VERSION "HIPBYYYYYYYYYYYYYYYYYYYYYYYYYYYYNNNNNNNNNN/4/%%%/4/'%**4NNN///"

NS_ :

BS_:

BU_: ADMM_05431 ADMM_05432 CSM_GmbH

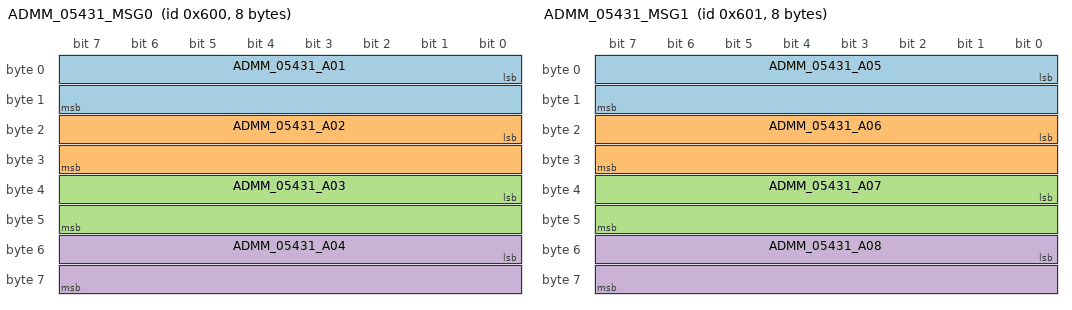
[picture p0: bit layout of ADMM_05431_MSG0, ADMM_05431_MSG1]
BO_ 1536 ADMM_05431_MSG0: 8 ADMM_05431
 SG_ ADMM_05431_A01 : 0|16@1- (0.00061037019,0) [-20|20] "V" CSM_GmbH
 SG_ ADMM_05431_A02 : 16|16@1- (0.00061037019,0) [-20|20] "V" CSM_GmbH
 SG_ ADMM_05431_A03 : 32|16@1- (0.00061037019,0) [-20|20] "V" CSM_GmbH
 SG_ ADMM_05431_A04 : 48|16@1- (0.00061037019,0) [-20|20] "V" CSM_GmbH

BO_ 1537 ADMM_05431_MSG1: 8 ADMM_05431
 SG_ ADMM_05431_A05 : 0|16@1- (0.00061037019,0) [-20|20] "V" CSM_GmbH
 SG_ ADMM_05431_A06 : 16|16@1- (0.00061037019,0) [-20|20] "V" CSM_GmbH
 SG_ ADMM_05431_A07 : 32|16@1- (0.00061037019,0) [-20|20] "V" CSM_GmbH
 SG_ ADMM_05431_A08 : 48|16@1- (0.00061037019,0) [-20|20] "V" CSM_GmbH

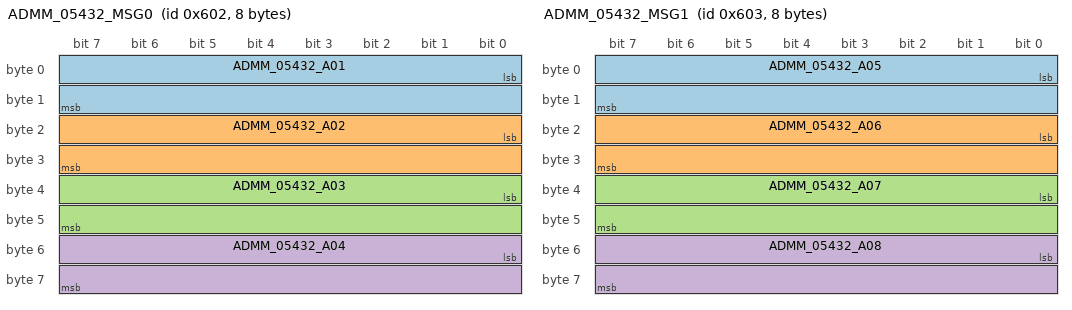
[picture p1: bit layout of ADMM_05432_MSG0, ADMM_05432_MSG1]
BO_ 1538 ADMM_05432_MSG0: 8 ADMM_05432
 SG_ ADMM_05432_A01 : 0|16@1- (0.00061037019,0) [-20|20] "V" CSM_GmbH
 SG_ ADMM_05432_A02 : 16|16@1- (0.00061037019,0) [-20|20] "V" CSM_GmbH
 SG_ ADMM_05432_A03 : 32|16@1- (0.00061037019,0) [-20|20] "V" CSM_GmbH
 SG_ ADMM_05432_A04 : 48|16@1- (0.00061037019,0) [-20|20] "V" CSM_GmbH

BO_ 1539 ADMM_05432_MSG1: 8 ADMM_05432
 SG_ ADMM_05432_A05 : 0|16@1- (0.00061037019,0) [-20|20] "V" CSM_GmbH
 SG_ ADMM_05432_A06 : 16|16@1- (0.00061037019,0) [-20|20] "V" CSM_GmbH
 SG_ ADMM_05432_A07 : 32|16@1- (0.00061037019,0) [-20|20] "V" CSM_GmbH
 SG_ ADMM_05432_A08 : 48|16@1- (0.00061037019,0) [-20|20] "V" CSM_GmbH

CM_ "CSM = 3, 11, 500000, 66, [305969] DBV(0) CONFIG(7.8.1.4033) IDINCR(1)";
CM_ BU_ ADMM_05431 "CSM = 3, MiniModulAD, 0, 8, 0x600, 0, 5431, 2, -ADMD, 1089, 0, 0, 0, 0, 15, 0x44303030, 4, 0x1";
CM_ SG_ 1536 ADMM_05431_A01 "CSM = 0, 0, 0, 0, 20, 1, 0, 0, 0, 0 ST(3) ZCMP(0,0)";
CM_ SG_ 1536 ADMM_05431_A02 "CSM = 0, 0, 0, 0, 20, 1, 0, 0, 0, 0 ST(3) ZCMP(0,0)";
CM_ SG_ 1536 ADMM_05431_A03 "CSM = 0, 0, 0, 0, 20, 1, 0, 0, 0, 0 ST(3) ZCMP(0,0)";
CM_ SG_ 1536 ADMM_05431_A04 "CSM = 0, 0, 0, 0, 20, 1, 0, 0, 0, 0 ST(3) ZCMP(0,0)";
CM_ SG_ 1537 ADMM_05431_A05 "CSM = 0, 0, 0, 0, 20, 1, 0, 0, 0, 0 ST(3) ZCMP(0,0)";
CM_ SG_ 1537 ADMM_05431_A06 "CSM = 0, 0, 0, 0, 20, 1, 0, 0, 0, 0 ST(3) ZCMP(0,0)";
CM_ SG_ 1537 ADMM_05431_A07 "CSM = 0, 0, 0, 0, 20, 1, 0, 0, 0, 0 ST(3) ZCMP(0,0)";
CM_ SG_ 1537 ADMM_05431_A08 "CSM = 0, 0, 0, 0, 20, 1, 0, 0, 0, 0 ST(3) ZCMP(0,0)";
CM_ BU_ ADMM_05432 "CSM = 3, MiniModulAD, 0, 8, 0x602, 0, 5432, 2, -ADMD, 1089, 0, 0, 0, 0, 15, 0x44303030, 4, 0x1";
CM_ SG_ 1538 ADMM_05432_A01 "CSM = 0, 0, 0, 0, 20, 1, 0, 0, 0, 0 ST(3) ZCMP(0,0)";
CM_ SG_ 1538 ADMM_05432_A02 "CSM = 0, 0, 0, 0, 20, 1, 0, 0, 0, 0 ST(3) ZCMP(0,0)";
CM_ SG_ 1538 ADMM_05432_A03 "CSM = 0, 0, 0, 0, 20, 1, 0, 0, 0, 0 ST(3) ZCMP(0,0)";
CM_ SG_ 1538 ADMM_05432_A04 "CSM = 0, 0, 0, 0, 20, 1, 0, 0, 0, 0 ST(3) ZCMP(0,0)";
CM_ SG_ 1539 ADMM_05432_A05 "CSM = 0, 0, 0, 0, 20, 1, 0, 0, 0, 0 ST(3) ZCMP(0,0)";
CM_ SG_ 1539 ADMM_05432_A06 "CSM = 0, 0, 0, 0, 20, 1, 0, 0, 0, 0 ST(3) ZCMP(0,0)";
CM_ SG_ 1539 ADMM_05432_A07 "CSM = 0, 0, 0, 0, 20, 1, 0, 0, 0, 0 ST(3) ZCMP(0,0)";
CM_ SG_ 1539 ADMM_05432_A08 "CSM = 0, 0, 0, 0, 20, 1, 0, 0, 0, 0 ST(3) ZCMP(0,0)";
BA_DEF_  "BusType" STRING ;
BA_DEF_ SG_ "CHNL_CMT" STRING ;
BA_DEF_ BU_ "Tables00" STRING ;
BA_DEF_ SG_ "UseTable" INT 0 8 ;
BA_DEF_DEF_  "BusType" "";
BA_DEF_DEF_ "CHNL_CMT" "";
BA_DEF_DEF_ "Tables00" "";
BA_DEF_DEF_ "UseTable" 0 ;
BA_ "BusType" "CAN";
BA_ "Tables00" BU_ ADMM_05431  "6C5B415A78DAEDC13101000000C2A0F54F6D0A3FA0000000000000781819880001";
BA_ "Tables00" BU_ ADMM_05432  "6C5B415A78DAEDC13101000000C2A0F54F6D0A3FA0000000000000781819880001";
